# GD32G5x3 register map
File version: 1.0
CPU: CM33 r2p1, little endian, MPU, FPU, 4 interrupt priority bits
Registers are 32-bit, read-write, reset 0x0 unless marked. A register's access mark holds for its fields unless they carry their own. Offsets are from the block's base; [hi:lo] are bit positions; {n}, {i} and the like mark numbered series.

## RCU — Reset and clock unit
Base 0x40021000
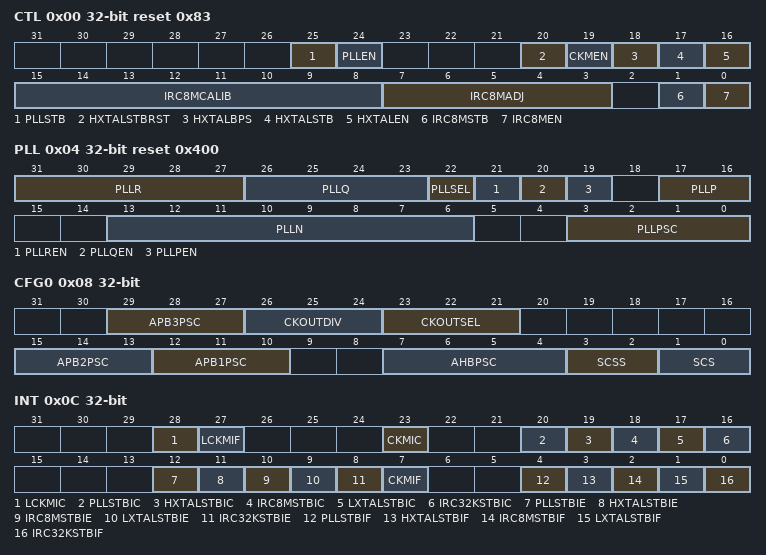
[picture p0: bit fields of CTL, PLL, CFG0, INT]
0x00 CTL access per field reset 0x83 — Control register
  [25] PLLSTB ro — PLL clock stabilization flag
  [24] PLLEN rw — PLL enable
  [20] HXTALSTBRST rw — HXTAL stabilization reset
  [19] CKMEN rw — HXTAL clock monitor enable
  [18] HXTALBPS rw — High speed crystal oscillator (HXTAL) clock bypass mode enable
  [17] HXTALSTB ro — High speed crystal oscillator (HXTAL) clock stabilization flag
  [16] HXTALEN rw — High speed crystal oscillator (HXTAL) Enable
  [15:8] IRC8MCALIB ro — Internal 8MHz RC Oscillator calibration value register
  [7:3] IRC8MADJ rw — Internal 8MHz RC Oscillator clock trim adjust value
  [1] IRC8MSTB ro — IRC8M internal 8MHz RC oscillator stabilization flag
  [0] IRC8MEN rw — Internal 8MHz RC oscillator enable
0x04 PLL reset 0x400
  [31:27] PLLR — The PLLR output frequency division factor from PLL VCO clock
  [26:23] PLLQ — The PLLQ output frequency division factor from PLL VCO clock
  [22] PLLSEL — PLL clock source selection
  [21] PLLREN — PLLR divider output enable
  [20] PLLQEN — PLLQ divider output enable
  [19] PLLPEN — PLLP divider output enable
  [17:16] PLLP — The PLLP output frequency division factor from PLL VCO clock
  [13:6] PLLN — The PLL VCO clock multiplication factor
  [3:0] PLLPSC — The PLL VCO source clock prescaler
0x08 CFG0 access per field — Clock configuration register 0
  [29:27] APB3PSC rw — APB3 prescaler selection
  [26:24] CKOUTDIV rw — The CK_OUT divider which the CK_OUT frequency can be reduced
  [23:21] CKOUTSEL rw — CK_OUT clock source selection
  [15:13] APB2PSC rw — APB2 prescaler selection
  [12:10] APB1PSC rw — APB1 prescaler selection
  [7:4] AHBPSC rw — AHB prescaler selection
  [3:2] SCSS ro — System clock switch status
  [1:0] SCS rw — System clock switch
0x0C INT access per field — Clock interrupt register
  [28] LCKMIC wo — LXTAL clock monitor interrupt clear
  [27] LCKMIF ro — LXTAL clock monitor interrupt flag
  [23] CKMIC wo — HXTAL clock stuck interrupt clear
  [20] PLLSTBIC wo — PLL stabilization interrupt clear
  [19] HXTALSTBIC wo — HXTAL stabilization interrupt clear
  [18] IRC8MSTBIC wo — IRC8M stabilization interrupt clear
  [17] LXTALSTBIC wo — LXTAL stabilization interrupt clear
  [16] IRC32KSTBIC wo — IRC32K stabilization interrupt clear
  [12] PLLSTBIE rw — PLL stabilization interrupt enable
  [11] HXTALSTBIE rw — HXTAL stabilization interrupt enable
  [10] IRC8MSTBIE rw — IRC8M stabilization interrupt enable
  [9] LXTALSTBIE rw — LXTAL stabilization interrupt enable
  [8] IRC32KSTBIE rw — IRC32K stabilization interrupt enable
  [7] CKMIF ro — HXTAL clock stuck interrupt flag
  [4] PLLSTBIF ro — PLL stabilization interrupt flag
  [3] HXTALSTBIF ro — HXTAL stabilization interrupt flag
  [2] IRC8MSTBIF ro — IRC8M stabilization interrupt flag
  [1] LXTALSTBIF ro — LXTAL stabilization interrupt flag
  [0] IRC32KSTBIF ro — IRC32K stabilization interrupt flag
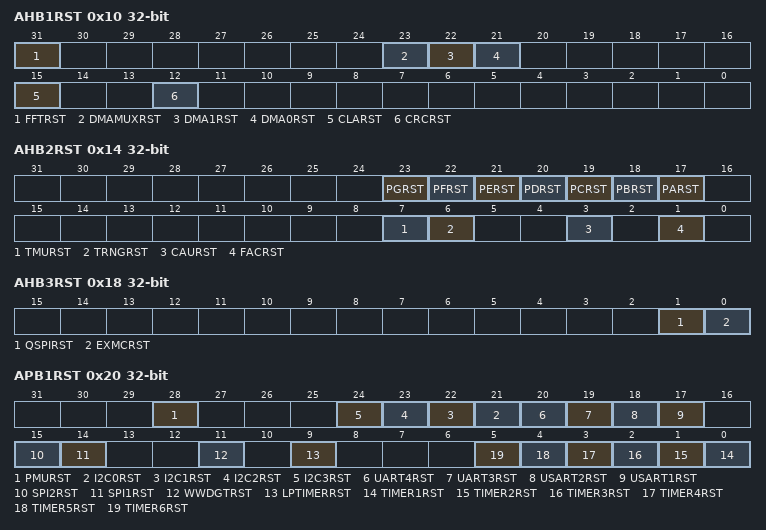
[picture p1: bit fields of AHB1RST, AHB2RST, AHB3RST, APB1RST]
0x10 AHB1RST — AHB1 reset register
  [31] FFTRST — FFT reset
  [23] DMAMUXRST — DMAMUX reset
  [22] DMA1RST — DMA1 reset
  [21] DMA0RST — DMA0 reset
  [15] CLARST — CLA reset
  [12] CRCRST — CRC reset
0x14 AHB2RST — AHB2 reset register
  [23] PGRST — GPIO port G reset
  [22] PFRST — GPIO portF reset
  [21] PERST — GPIO port E reset
  [20] PDRST — GPIO port D reset
  [19] PCRST — GPIO port C reset
  [18] PBRST — GPIO port B reset
  [17] PARST — GPIO port A reset
  [7] TMURST — TMU reset
  [6] TRNGRST — TRNG reset
  [3] CAURST — CAU reset
  [1] FACRST — FAC reset
0x18 AHB3RST — AHB3 reset register
  [1] QSPIRST — QSPI reset
  [0] EXMCRST — EXMC reset
0x20 APB1RST — APB1 reset register
  [28] PMURST — Power control reset
  [n+21] I2C{n}RST (n=0..3) — I2C{n} reset
  [20] UART4RST — UART4 reset
  [19] UART3RST — UART3 reset
  [18] USART2RST — USART2 reset
  [17] USART1RST — USART1 reset
  [15] SPI2RST — SPI2 reset
  [14] SPI1RST — SPI1 reset
  [11] WWDGTRST — WWDGT reset
  [9] LPTIMERRST — LPTIMER reset
  [n-1] TIMER{n}RST (n=1..6) — TIMER{n} reset
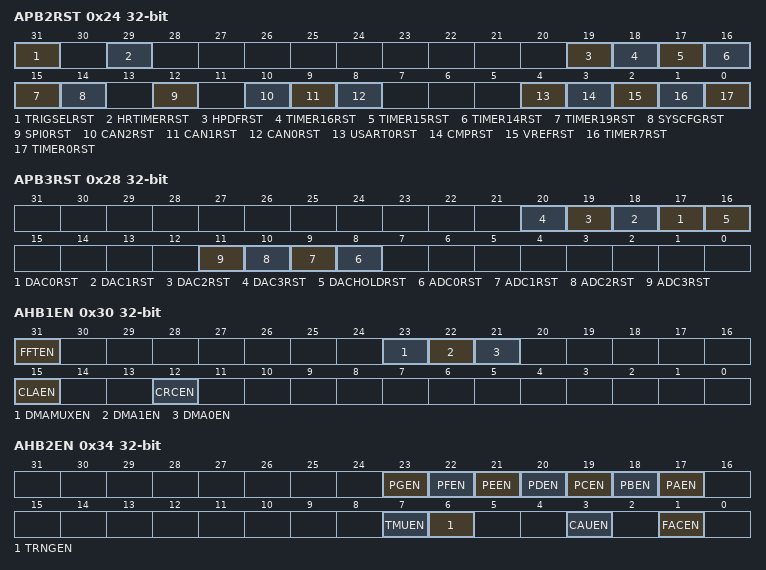
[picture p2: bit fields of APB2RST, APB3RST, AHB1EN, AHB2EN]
0x24 APB2RST — APB2 reset register
  [31] TRIGSELRST — TRIGSELreset
  [29] HRTIMERRST — HRTIMER reset
  [19] HPDFRST — HPDF reset
  [18] TIMER16RST — TIMER16 reset
  [17] TIMER15RST — TIMER15 reset
  [16] TIMER14RST — TIMER14 reset
  [15] TIMER19RST — TIMER19 reset
  [14] SYSCFGRST — SYSCFG reset
  [12] SPI0RST — SPI0 reset
  [10] CAN2RST — CAN2 reset
  [9] CAN1RST — CAN1 reset
  [8] CAN0RST — CAN0 reset
  [4] USART0RST — USART0 reset
  [3] CMPRST — CMP reset
  [2] VREFRST — VREF reset
  [1] TIMER7RST — TIMER7 reset
  [0] TIMER0RST — TIMER0 reset
0x28 APB3RST — APB3 reset register
  [n+17] DAC{n}RST (n=0..3) — DAC{n} reset
  [16] DACHOLDRST — DAC hold clock reset
  [n+8] ADC{n}RST (n=0..3) — ADC{n} reset
0x30 AHB1EN — AHB1 enable register
  [31] FFTEN — FFT clock enable
  [23] DMAMUXEN — DMAMUX clock enable
  [22] DMA1EN — DMA1 clock enable
  [21] DMA0EN — DMA0 clock enable
  [15] CLAEN — CLA clock enable
  [12] CRCEN — CRC clock enable
0x34 AHB2EN — AHB2 enable register
  [23] PGEN — GPIO port G clock enable
  [22] PFEN — GPIO port F clock enable
  [21] PEEN — GPIO port E clock enable
  [20] PDEN — GPIO port D clock enable
  [19] PCEN — GPIO port C clock enable
  [18] PBEN — GPIO port B clock enable
  [17] PAEN — GPIO port A clock enable
  [7] TMUEN — TMU clock enable
  [6] TRNGEN — TRNG clock enable
  [3] CAUEN — CRY clock enable
  [1] FACEN — FAC clock enable
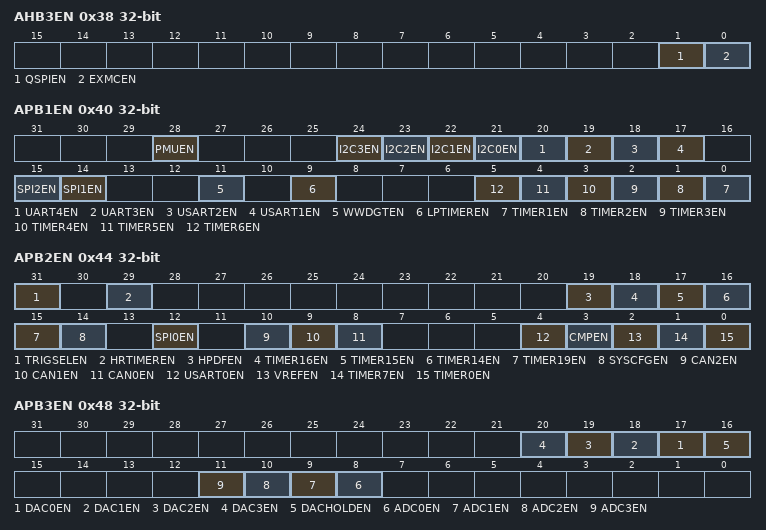
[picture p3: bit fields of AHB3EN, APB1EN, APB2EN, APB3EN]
0x38 AHB3EN — AHB3 enable register
  [1] QSPIEN — QSPI clock enable
  [0] EXMCEN — EXMC clock enable
0x40 APB1EN — APB1 enable register
  [28] PMUEN — PMU clock enable
  [n+21] I2C{n}EN (n=0..3) — I2C{n} clock enable
  [20] UART4EN — UART4 clock enable
  [19] UART3EN — UART3 clock enable
  [18] USART2EN — USART2 clock enable
  [17] USART1EN — USART1 clock enable
  [15] SPI2EN — SPI2 clock enable
  [14] SPI1EN — SPI1 clock enable
  [11] WWDGTEN — WWDGT clock enable
  [9] LPTIMEREN — LPTIMER clock enable
  [n-1] TIMER{n}EN (n=1..6) — TIMER{n} clock enable
0x44 APB2EN — APB2 enable register
  [31] TRIGSELEN — TRIGSEL clock enable
  [29] HRTIMEREN — HRTIMER clock enable
  [19] HPDFEN — HPDF clock enable
  [18] TIMER16EN — TIMER16 clock enable
  [17] TIMER15EN — TIMER15 clock enable
  [16] TIMER14EN — TIMER14 clock enable
  [15] TIMER19EN — TIMER19 clock enable
  [14] SYSCFGEN — SYSCFG clock enable
  [12] SPI0EN — SPI0 clock enable
  [10] CAN2EN — CAN2 clock enable
  [9] CAN1EN — CAN1 clock enable
  [8] CAN0EN — CAN0 clock enable
  [4] USART0EN — USART0 clock enable
  [3] CMPEN — CMP clock enable
  [2] VREFEN — VREF clock enable
  [1] TIMER7EN — TIMER7 clock enable
  [0] TIMER0EN — TIMER0 clock enable
0x48 APB3EN — APB3 enable register
  [n+17] DAC{n}EN (n=0..3) — DAC{n} clock enable
  [16] DACHOLDEN — DAC hold clock clock enable
  [n+8] ADC{n}EN (n=0..3) — ADC{n} clock enable
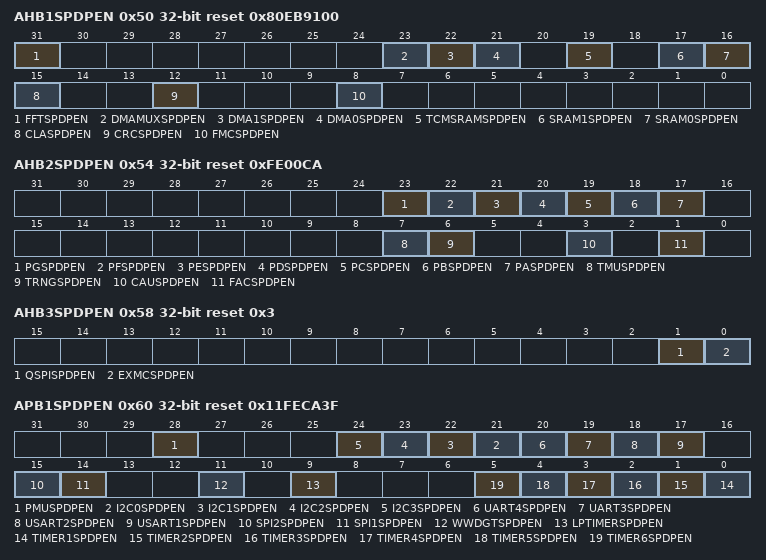
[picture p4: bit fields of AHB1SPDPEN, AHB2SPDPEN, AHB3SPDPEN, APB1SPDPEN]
0x50 AHB1SPDPEN reset 0x80EB9100 — AHB1 sleep and deep-sleep mode enable register
  [31] FFTSPDPEN — FFT clock enable when sleep and deep sleep mode
  [23] DMAMUXSPDPEN — DMAMUX clock enable when sleep and deep sleep mode
  [22] DMA1SPDPEN — DMA1 clock enable when sleep and deep sleep mode
  [21] DMA0SPDPEN — DMA0 clock enable when sleep and deep sleep mode
  [19] TCMSRAMSPDPEN — TCMSRAM enable when sleep and deep sleep mode
  [17] SRAM1SPDPEN — SRAM1 enable when sleep and deep sleep mode
  [16] SRAM0SPDPEN — SRAM0 enable when sleep and deep sleep mode
  [15] CLASPDPEN — CLA clock enable when sleep and deep sleep mode
  [12] CRCSPDPEN — CRC clock enable when sleep and deep sleep mode
  [8] FMCSPDPEN — FMC clock enable when sleep and deep sleep mode
0x54 AHB2SPDPEN reset 0xFE00CA — AHB2 sleep and deep-sleep mode enable register
  [23] PGSPDPEN — GPIO port G clock enable when sleep and deep sleep mode
  [22] PFSPDPEN — GPIO port F clock enable when sleep and deep sleep mode
  [21] PESPDPEN — GPIO port E clock enable when sleep and deep sleep mode
  [20] PDSPDPEN — GPIO port D clock enable when sleep and deep sleep mode
  [19] PCSPDPEN — GPIO port C clock enable when sleep and deep sleep mode
  [18] PBSPDPEN — GPIO port B clock enable when sleep and deep sleep mode
  [17] PASPDPEN — GPIO port A clock enable when sleep and deep sleep mode
  [7] TMUSPDPEN — TMU clock enable when sleep and deep sleep mode
  [6] TRNGSPDPEN — TRNG clock enable when sleep and deep sleep mode
  [3] CAUSPDPEN — CAU clock enable when sleep and deep sleep mode
  [1] FACSPDPEN — FAC clock enable when sleep and deep sleep mode
0x58 AHB3SPDPEN reset 0x3 — AHB3 sleep and deep-sleep mode enable register
  [1] QSPISPDPEN — QSPI clock enable when sleep and deep sleep mode
  [0] EXMCSPDPEN — EXMC clock enable when sleep and deep sleep mode
0x60 APB1SPDPEN reset 0x11FECA3F — APB1 sleep and deep-sleep mode enable register
  [28] PMUSPDPEN — PMU clock enable when sleep and deep sleep mode
  [n+21] I2C{n}SPDPEN (n=0..3) — I2C{n} clock enable when sleep and deep sleep mode
  [20] UART4SPDPEN — UART4 clock enable when sleep and deep sleep mode
  [19] UART3SPDPEN — UART3 clock enable when sleep and deep sleep mode
  [18] USART2SPDPEN — USART2 clock enable when sleep and deep sleep mode
  [17] USART1SPDPEN — USART1 clock enable when sleep and deep sleep mode
  [15] SPI2SPDPEN — SPI2 clock enable when sleep and deep sleep mode
  [14] SPI1SPDPEN — SPI1 clock enable when sleep and deep sleep mode
  [11] WWDGTSPDPEN — WWDGT clock enable when sleep and deep sleep mode
  [9] LPTIMERSPDPEN — LPTIMER clock enable when sleep and deep sleep mode
  [n-1] TIMER{n}SPDPEN (n=1..6) — TIMER{n} clock enable when sleep and deep sleep mode
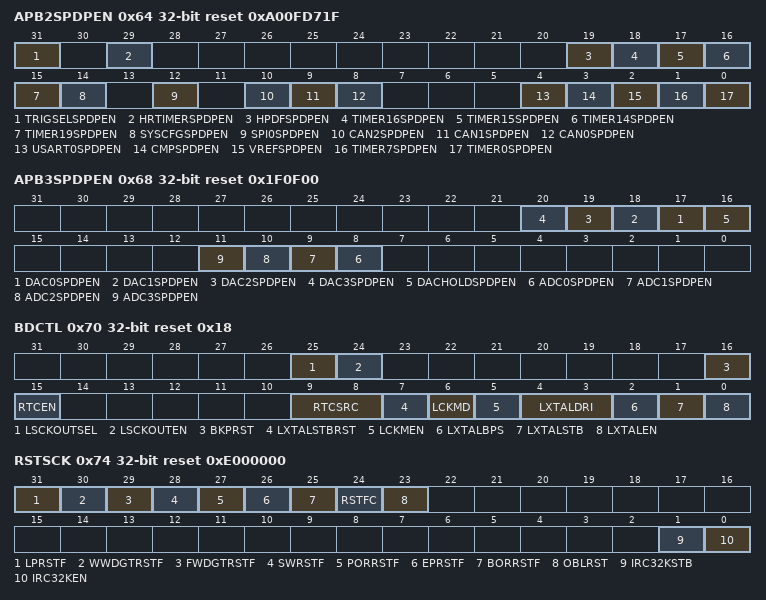
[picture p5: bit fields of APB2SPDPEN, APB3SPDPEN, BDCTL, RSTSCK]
0x64 APB2SPDPEN reset 0xA00FD71F — APB2 sleep and deep-sleep mode enable register
  [31] TRIGSELSPDPEN — TRIGSEL clock enable when sleep mode
  [29] HRTIMERSPDPEN — HRTIMER clock enable when sleep and deep sleep mode
  [19] HPDFSPDPEN — HPDF clock enable when sleep and deep sleep mode
  [18] TIMER16SPDPEN — TIMER16 clock enable when sleep and deep sleep mode
  [17] TIMER15SPDPEN — TIMER15 clock enable when sleep and deep sleep mode
  [16] TIMER14SPDPEN — TIMER14 clock enable when sleep and deep sleep mode
  [15] TIMER19SPDPEN — TIMER19 clock enable when sleep and deep sleep mode
  [14] SYSCFGSPDPEN — SYSCFG clock enable when sleep and deep sleep mode
  [12] SPI0SPDPEN — SPI0 clock enable when sleep and deep sleep mode
  [10] CAN2SPDPEN — CAN2 clock enable when sleep and deep sleep mode
  [9] CAN1SPDPEN — CAN1 clock enable when sleep and deep sleep mode
  [8] CAN0SPDPEN — CAN0 clock enable when sleep and deep sleep mode
  [4] USART0SPDPEN — USART0 clock enable when sleep and deep sleep mode
  [3] CMPSPDPEN — CMP clock enable when sleep and deep sleep mode
  [2] VREFSPDPEN — VREF clock enable when sleep and deep sleep mode
  [1] TIMER7SPDPEN — TIMER7 clock enable when sleep and deep sleep mode
  [0] TIMER0SPDPEN — TIMER0 clock enable when sleep and deep sleep mode
0x68 APB3SPDPEN reset 0x1F0F00 — APB3 sleep and deep-sleep mode enable register
  [n+17] DAC{n}SPDPEN (n=0..3) — DAC{n} clock enable when sleep and deep sleep mode
  [16] DACHOLDSPDPEN — DAC hold clock clock enable when sleep and deep sleep mode
  [n+8] ADC{n}SPDPEN (n=0..3) — ADC{n} clock enable when sleep and deep sleep mode
0x70 BDCTL access per field reset 0x18 — Backup domain control register
  [25] LSCKOUTSEL rw — Low speed clock output selection
  [24] LSCKOUTEN rw — Low speed clock output enalbe
  [16] BKPRST rw — Backup domain reset
  [15] RTCEN rw — RTC clock enable
  [9:8] RTCSRC rw — RTC clock entry selection
  [7] LXTALSTBRST rw — LXTAL stabilization reset
  [6] LCKMD rw — LXTALclock failure detection
  [5] LCKMEN rw — LXTAL clock monitor enable
  [4:3] LXTALDRI rw — LXTAL drive capability
  [2] LXTALBPS rw — LXTAL bypass mode enable
  [1] LXTALSTB ro — Low speed crystal oscillator stabilization flag
  [0] LXTALEN rw — LXTAL enable
0x74 RSTSCK access per field reset 0xE000000 — Reset source/clock register
  [31] LPRSTF ro — Low-power reset flag
  [30] WWDGTRSTF ro — Window watchdog timer reset flag
  [29] FWDGTRSTF ro — Free watchdog timer reset flag
  [28] SWRSTF ro — Software reset flag
  [27] PORRSTF ro — Power reset flag
  [26] EPRSTF ro — External PIN reset flag
  [25] BORRSTF ro — BOR reset flag
  [24] RSTFC rw — Reset flag clear
  [23] OBLRST ro — Option byte loader reset flag
  [1] IRC32KSTB ro — IRC32K stabilization flag
  [0] IRC32KEN rw — IRC32K enable
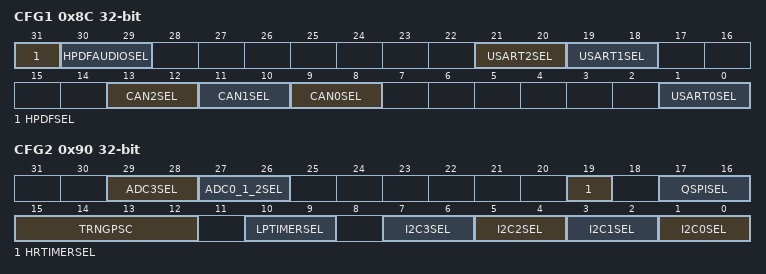
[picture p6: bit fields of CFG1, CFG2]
0x8C CFG1 — Clock configuration register 1
  [31] HPDFSEL — HPDF clock source selection
  [30:29] HPDFAUDIOSEL — HPDF AUDIO clock source selection
  [21:20] USART2SEL — USART2 clock source selection
  [19:18] USART1SEL — USART1 clock source selection
  [13:12] CAN2SEL — CAN2 clock source selection
  [11:10] CAN1SEL — CAN1 clock selection
  [9:8] CAN0SEL — CAN0 clock source selection
  [1:0] USART0SEL — USART0 clock source selection
0x90 CFG2 — Clock configuration register 2
  [29:28] ADC3SEL — ADC3 clock source selection
  [27:26] ADC0_1_2SEL — ADC0 / 1 / 2 clock source selection
  [19] HRTIMERSEL — HRTIMER clock source selection
  [17:16] QSPISEL — QSPI clock source selection
  [15:12] TRNGPSC — TRNG prescaler selection
  [10:9] LPTIMERSEL — LPTIMER clock source selection
  [2n+1:2n] I2C{n}SEL (n=0..3) — I2C{n} clock source selection
